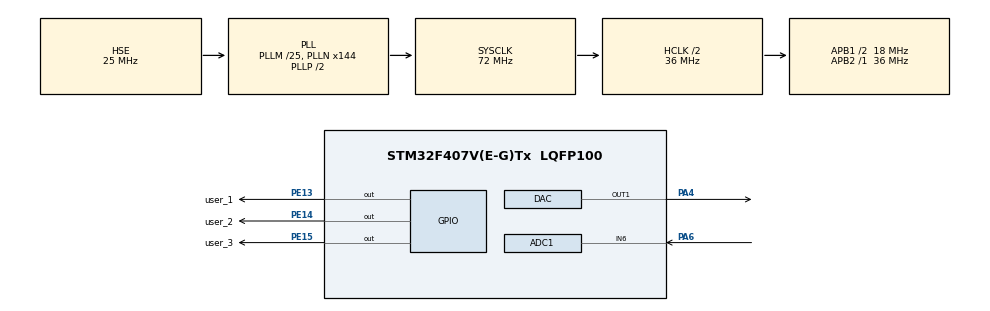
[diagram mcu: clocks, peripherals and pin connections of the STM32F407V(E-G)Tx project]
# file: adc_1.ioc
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ADC1.Channel-3\#ChannelRegularConversion=ADC_CHANNEL_6
ADC1.ClockPrescaler=ADC_CLOCK_SYNC_PCLK_DIV2
ADC1.ContinuousConvMode=ENABLE
ADC1.DMAContinuousRequests=ENABLE
ADC1.DataAlign=ADC_DATAALIGN_RIGHT
ADC1.DiscontinuousConvMode=DISABLE
ADC1.EOCSelection=ADC_EOC_SINGLE_CONV
ADC1.EnableAnalogWatchDog=false
ADC1.ExternalTrigConv=ADC_SOFTWARE_START
ADC1.ExternalTrigConvEdge=ADC_EXTERNALTRIGCONVEDGE_NONE
ADC1.InjNumberOfConversion=0
ADC1.NbrOfConversion=1
ADC1.NbrOfConversionFlag=1
ADC1.Rank-3\#ChannelRegularConversion=1
ADC1.Resolution=ADC_RESOLUTION_12B
ADC1.SamplingTime-3\#ChannelRegularConversion=ADC_SAMPLETIME_3CYCLES
ADC1.ScanConvMode=DISABLE
ADC1.master=1
DAC.DAC_OutputBuffer=DAC_OUTPUTBUFFER_DISABLE
DAC.DAC_Trigger=DAC_TRIGGER_T7_TRGO
DAC.WaveGeneration=DISABLE
Dma.ADC1.1.Direction=DMA_PERIPH_TO_MEMORY
Dma.ADC1.1.FIFOMode=DMA_FIFOMODE_DISABLE
Dma.ADC1.1.Instance=DMA2_Stream0
Dma.ADC1.1.MemDataAlignment=DMA_MDATAALIGN_HALFWORD
Dma.ADC1.1.MemInc=DMA_MINC_ENABLE
Dma.ADC1.1.Mode=DMA_NORMAL
Dma.ADC1.1.PeriphDataAlignment=DMA_PDATAALIGN_HALFWORD
Dma.ADC1.1.PeriphInc=DMA_PINC_DISABLE
Dma.ADC1.1.Priority=DMA_PRIORITY_LOW
Dma.DAC1.0.Direction=DMA_MEMORY_TO_PERIPH
Dma.DAC1.0.FIFOMode=DMA_FIFOMODE_DISABLE
Dma.DAC1.0.Instance=DMA1_Stream5
Dma.DAC1.0.MemDataAlignment=DMA_MDATAALIGN_HALFWORD
Dma.DAC1.0.MemInc=DMA_MINC_ENABLE
Dma.DAC1.0.Mode=DMA_CIRCULAR
Dma.DAC1.0.PeriphDataAlignment=DMA_PDATAALIGN_HALFWORD
Dma.DAC1.0.PeriphInc=DMA_PINC_DISABLE
Dma.DAC1.0.Priority=DMA_PRIORITY_LOW
Dma.Request0=DAC1
Dma.Request1=ADC1
Mcu.Family=STM32F4
Mcu.Name=STM32F407V(E-G)Tx
Mcu.Package=LQFP100
NVIC.DMA1_Stream5_IRQn=true\:0\:0\:false\:false\:true\:false
NVIC.DMA2_Stream0_IRQn=true\:0\:0\:false\:false\:true\:false
NVIC.PriorityGroup=NVIC_PRIORITYGROUP_4
NVIC.TIM7_IRQn=true\:0\:0\:false\:false\:true\:true
PA13.Mode=Serial_Wire
PA13.Signal=SYS_JTMS-SWDIO
PA14.Mode=Serial_Wire
PA14.Signal=SYS_JTCK-SWCLK
PA4.Signal=SharedAnalog_PA4
PA6.Signal=SharedAnalog_PA6
PE13.GPIO_Label=user_1
PE13.GPIO_PuPd=GPIO_NOPULL
PE13.Signal=GPIO_Output
PE14.GPIO_Label=user_2
PE14.GPIO_PuPd=GPIO_NOPULL
PE14.Signal=GPIO_Output
PE15.GPIO_Label=user_3
PE15.GPIO_PuPd=GPIO_NOPULL
PE15.Signal=GPIO_Output
PH0-OSC_IN.Mode=HSE-External-Oscillator
PH0-OSC_IN.Signal=RCC_OSC_IN
PH1-OSC_OUT.Mode=HSE-External-Oscillator
PH1-OSC_OUT.Signal=RCC_OSC_OUT
ProjectManager.HeapSize=0x200
ProjectManager.StackSize=0x400
ProjectManager.TargetToolchain=MDK-ARM V5
RCC.48MHZClocksFreq_Value=36000000
RCC.AHBCLKDivider=RCC_SYSCLK_DIV2
RCC.AHBFreq_Value=36000000
RCC.APB1CLKDivider=RCC_HCLK_DIV2
RCC.APB1Freq_Value=18000000
RCC.APB1TimFreq_Value=36000000
RCC.APB2Freq_Value=36000000
RCC.APB2TimFreq_Value=36000000
RCC.CortexFreq_Value=36000000
RCC.HCLKFreq_Value=36000000
RCC.HSE_VALUE=25000000
RCC.HSI_VALUE=16000000
RCC.LSE_VALUE=32768
RCC.PLLM=25
RCC.PLLN=144
RCC.PLLSourceVirtual=RCC_PLLSOURCE_HSE
RCC.SYSCLKFreq_VALUE=72000000
RCC.SYSCLKSource=RCC_SYSCLKSOURCE_PLLCLK
RCC.VCOOutputFreq_Value=144000000
SH.SharedAnalog_PA4.0=GPIO_Analog
SH.SharedAnalog_PA4.1=DAC_OUT1,DAC_OUT1
SH.SharedAnalog_PA6.0=GPIO_Analog
SH.SharedAnalog_PA6.1=ADC1_IN6,IN6
TIM7.Period=12-1
TIM7.Prescaler=1000-1
TIM7.TIM_MasterOutputTrigger=TIM_TRGO_UPDATE
VP_TIM7_VS_ClockSourceINT.Mode=Enable_Timer
board=custom

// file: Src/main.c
/**
  ******************************************************************************
  * @file           : main.c
  * @brief          : Main program body
  ******************************************************************************
  ** This notice applies to any and all portions of this file
  * that are not between comment pairs USER CODE BEGIN and
  * USER CODE END. Other portions of this file, whether
  * inserted by the user or by software development tools
  * are owned by their respective copyright owners.
  *
  * COPYRIGHT(c) 2021 STMicroelectronics
  *
  * Redistribution and use in source and binary forms, with or without modification,
  * are permitted provided that the following conditions are met:
  *   1. Redistributions of source code must retain the above copyright notice,
  *      this list of conditions and the following disclaimer.
  *   2. Redistributions in binary form must reproduce the above copyright notice,
  *      this list of conditions and the following disclaimer in the documentation
  *      and/or other materials provided with the distribution.
  *   3. Neither the name of STMicroelectronics nor the names of its contributors
  *      may be used to endorse or promote products derived from this software
  *      without specific prior written permission.
  *
  * THIS SOFTWARE IS PROVIDED BY THE COPYRIGHT HOLDERS AND CONTRIBUTORS "AS IS"
  * AND ANY EXPRESS OR IMPLIED WARRANTIES, INCLUDING, BUT NOT LIMITED TO, THE
  * IMPLIED WARRANTIES OF MERCHANTABILITY AND FITNESS FOR A PARTICULAR PURPOSE ARE
  * DISCLAIMED. IN NO EVENT SHALL THE COPYRIGHT HOLDER OR CONTRIBUTORS BE LIABLE
  * FOR ANY DIRECT, INDIRECT, INCIDENTAL, SPECIAL, EXEMPLARY, OR CONSEQUENTIAL
  * DAMAGES (INCLUDING, BUT NOT LIMITED TO, PROCUREMENT OF SUBSTITUTE GOODS OR
  * SERVICES; LOSS OF USE, DATA, OR PROFITS; OR BUSINESS INTERRUPTION) HOWEVER
  * CAUSED AND ON ANY THEORY OF LIABILITY, WHETHER IN CONTRACT, STRICT LIABILITY,
  * OR TORT (INCLUDING NEGLIGENCE OR OTHERWISE) ARISING IN ANY WAY OUT OF THE USE
  * OF THIS SOFTWARE, EVEN IF ADVISED OF THE POSSIBILITY OF SUCH DAMAGE.
  *
  ******************************************************************************
  */
#include "main.h"
#include "stm32f4xx_hal.h"

ADC_HandleTypeDef hadc1;
DMA_HandleTypeDef hdma_adc1;

DAC_HandleTypeDef hdac;
DMA_HandleTypeDef hdma_dac1;

TIM_HandleTypeDef htim7;

/* USER CODE BEGIN PV */
/* Private variables ---------------------------------------------------------*/
 #define adc_buf 4096
	uint32_t adc_Result[adc_buf];
/* USER CODE END PV */

void SystemClock_Config(void);
static void MX_GPIO_Init(void);
static void MX_DMA_Init(void);
static void MX_ADC1_Init(void);
static void MX_DAC_Init(void);
static void MX_TIM7_Init(void);

/* USER CODE BEGIN PFP */
/* Private function prototypes -----------------------------------------------*/

/* USER CODE END PFP */

/* USER CODE BEGIN 0 */
void HAL_TIM_PeriodElapsedCallback(TIM_HandleTypeDef *htim){
	int i = 0;
			HAL_ADC_Start_DMA(&hadc1, (uint32_t *)adc_Result,adc_buf);
 		adc_Result[i] = HAL_ADC_GetValue(&hadc1);

		HAL_ADC_Stop_DMA(&hadc1);

	//	HAL_Delay(1);
		HAL_DAC_Start_DMA(&hdac, DAC1_CHANNEL_1,(uint32_t *)adc_Result, adc_buf, DAC_ALIGN_12B_R);
		HAL_DAC_SetValue(&hdac, DAC1_CHANNEL_1, DAC_ALIGN_12B_R, adc_Result[i]);
		i++;
		if (i==adc_buf)
			i = 0;

}

/* USER CODE END 0 */

int main(void)
{

  /* MCU Configuration----------------------------------------------------------*/

  /* Reset of all peripherals, Initializes the Flash interface and the Systick. */
  HAL_Init();

  /* Configure the system clock */
  SystemClock_Config();

  /* Initialize all configured peripherals */
  MX_GPIO_Init();
  MX_DMA_Init();
  MX_ADC1_Init();
  MX_DAC_Init();
  MX_TIM7_Init();
  /* USER CODE BEGIN 2 */
//	int i = 0;
	HAL_TIM_Base_Start_IT(&htim7);
  /* USER CODE END 2 */

  /* Infinite loop */
  while (1)
  {

	}

}

void SystemClock_Config(void)
{

  RCC_OscInitTypeDef RCC_OscInitStruct;
  RCC_ClkInitTypeDef RCC_ClkInitStruct;

    /**Configure the main internal regulator output voltage
    */
  __HAL_RCC_PWR_CLK_ENABLE();

  __HAL_PWR_VOLTAGESCALING_CONFIG(PWR_REGULATOR_VOLTAGE_SCALE1);

    /**Initializes the CPU, AHB and APB busses clocks
    */
  RCC_OscInitStruct.OscillatorType = RCC_OSCILLATORTYPE_HSE;
  RCC_OscInitStruct.HSEState = RCC_HSE_ON;
  RCC_OscInitStruct.PLL.PLLState = RCC_PLL_ON;
  RCC_OscInitStruct.PLL.PLLSource = RCC_PLLSOURCE_HSE;
  RCC_OscInitStruct.PLL.PLLM = 25;
  RCC_OscInitStruct.PLL.PLLN = 144;
  RCC_OscInitStruct.PLL.PLLP = RCC_PLLP_DIV2;
  RCC_OscInitStruct.PLL.PLLQ = 4;
  if (HAL_RCC_OscConfig(&RCC_OscInitStruct) != HAL_OK)
  {
    _Error_Handler(__FILE__, __LINE__);
  }

    /**Initializes the CPU, AHB and APB busses clocks
    */
  RCC_ClkInitStruct.ClockType = RCC_CLOCKTYPE_HCLK|RCC_CLOCKTYPE_SYSCLK
                              |RCC_CLOCKTYPE_PCLK1|RCC_CLOCKTYPE_PCLK2;
  RCC_ClkInitStruct.SYSCLKSource = RCC_SYSCLKSOURCE_PLLCLK;
  RCC_ClkInitStruct.AHBCLKDivider = RCC_SYSCLK_DIV2;
  RCC_ClkInitStruct.APB1CLKDivider = RCC_HCLK_DIV2;
  RCC_ClkInitStruct.APB2CLKDivider = RCC_HCLK_DIV1;

  if (HAL_RCC_ClockConfig(&RCC_ClkInitStruct, FLASH_LATENCY_1) != HAL_OK)
  {
    _Error_Handler(__FILE__, __LINE__);
  }

    /**Configure the Systick interrupt time
    */
  HAL_SYSTICK_Config(HAL_RCC_GetHCLKFreq()/1000);

    /**Configure the Systick
    */
  HAL_SYSTICK_CLKSourceConfig(SYSTICK_CLKSOURCE_HCLK);

  /* SysTick_IRQn interrupt configuration */
  HAL_NVIC_SetPriority(SysTick_IRQn, 0, 0);
}

/* ADC1 init function */
static void MX_ADC1_Init(void)
{

  ADC_ChannelConfTypeDef sConfig;

    /**Configure the global features of the ADC (Clock, Resolution, Data Alignment and number of conversion)
    */
  hadc1.Instance = ADC1;
  hadc1.Init.ClockPrescaler = ADC_CLOCK_SYNC_PCLK_DIV2;
  hadc1.Init.Resolution = ADC_RESOLUTION_12B;
  hadc1.Init.ScanConvMode = DISABLE;
  hadc1.Init.ContinuousConvMode = ENABLE;
  hadc1.Init.DiscontinuousConvMode = DISABLE;
  hadc1.Init.ExternalTrigConvEdge = ADC_EXTERNALTRIGCONVEDGE_NONE;
  hadc1.Init.ExternalTrigConv = ADC_SOFTWARE_START;
  hadc1.Init.DataAlign = ADC_DATAALIGN_RIGHT;
  hadc1.Init.NbrOfConversion = 1;
  hadc1.Init.DMAContinuousRequests = ENABLE;
  hadc1.Init.EOCSelection = ADC_EOC_SINGLE_CONV;
  if (HAL_ADC_Init(&hadc1) != HAL_OK)
  {
    _Error_Handler(__FILE__, __LINE__);
  }

    /**Configure for the selected ADC regular channel its corresponding rank in the sequencer and its sample time.
    */
  sConfig.Channel = ADC_CHANNEL_6;
  sConfig.Rank = 1;
  sConfig.SamplingTime = ADC_SAMPLETIME_3CYCLES;
  if (HAL_ADC_ConfigChannel(&hadc1, &sConfig) != HAL_OK)
  {
    _Error_Handler(__FILE__, __LINE__);
  }

}

/* DAC init function */
static void MX_DAC_Init(void)
{

  DAC_ChannelConfTypeDef sConfig;

    /**DAC Initialization
    */
  hdac.Instance = DAC;
  if (HAL_DAC_Init(&hdac) != HAL_OK)
  {
    _Error_Handler(__FILE__, __LINE__);
  }

    /**DAC channel OUT1 config
    */
  sConfig.DAC_Trigger = DAC_TRIGGER_T7_TRGO;
  sConfig.DAC_OutputBuffer = DAC_OUTPUTBUFFER_DISABLE;
  if (HAL_DAC_ConfigChannel(&hdac, &sConfig, DAC_CHANNEL_1) != HAL_OK)
  {
    _Error_Handler(__FILE__, __LINE__);
  }

}

/* TIM7 init function */
static void MX_TIM7_Init(void)
{

  TIM_MasterConfigTypeDef sMasterConfig;

  htim7.Instance = TIM7;
  htim7.Init.Prescaler = 1000-1;
  htim7.Init.CounterMode = TIM_COUNTERMODE_UP;
  htim7.Init.Period = 12-1;
  if (HAL_TIM_Base_Init(&htim7) != HAL_OK)
  {
    _Error_Handler(__FILE__, __LINE__);
  }

  sMasterConfig.MasterOutputTrigger = TIM_TRGO_UPDATE;
  sMasterConfig.MasterSlaveMode = TIM_MASTERSLAVEMODE_DISABLE;
  if (HAL_TIMEx_MasterConfigSynchronization(&htim7, &sMasterConfig) != HAL_OK)
  {
    _Error_Handler(__FILE__, __LINE__);
  }

}

static void MX_DMA_Init(void)
{
  /* DMA controller clock enable */
  __HAL_RCC_DMA1_CLK_ENABLE();
  __HAL_RCC_DMA2_CLK_ENABLE();

  /* DMA interrupt init */
  /* DMA1_Stream5_IRQn interrupt configuration */
  HAL_NVIC_SetPriority(DMA1_Stream5_IRQn, 0, 0);
  HAL_NVIC_EnableIRQ(DMA1_Stream5_IRQn);
  /* DMA2_Stream0_IRQn interrupt configuration */
  HAL_NVIC_SetPriority(DMA2_Stream0_IRQn, 0, 0);
  HAL_NVIC_EnableIRQ(DMA2_Stream0_IRQn);

}

/** Configure pins as
        * Analog
        * Input
        * Output
        * EVENT_OUT
        * EXTI
     PA4   ------> SharedAnalog_PA4
     PA6   ------> SharedAnalog_PA6
*/
static void MX_GPIO_Init(void)
{

  GPIO_InitTypeDef GPIO_InitStruct;

  /* GPIO Ports Clock Enable */
  __HAL_RCC_GPIOH_CLK_ENABLE();
  __HAL_RCC_GPIOA_CLK_ENABLE();
  __HAL_RCC_GPIOE_CLK_ENABLE();

  /*Configure GPIO pin Output Level */
  HAL_GPIO_WritePin(GPIOE, user_1_Pin|user_2_Pin|user_3_Pin, GPIO_PIN_RESET);

  /*Configure GPIO pins : PA4 PA6 */
  GPIO_InitStruct.Pin = GPIO_PIN_4|GPIO_PIN_6;
  GPIO_InitStruct.Mode = GPIO_MODE_ANALOG;
  GPIO_InitStruct.Pull = GPIO_NOPULL;
  HAL_GPIO_Init(GPIOA, &GPIO_InitStruct);

  /*Configure GPIO pins : user_1_Pin user_2_Pin user_3_Pin */
  GPIO_InitStruct.Pin = user_1_Pin|user_2_Pin|user_3_Pin;
  GPIO_InitStruct.Mode = GPIO_MODE_OUTPUT_PP;
  GPIO_InitStruct.Pull = GPIO_NOPULL;
  GPIO_InitStruct.Speed = GPIO_SPEED_FREQ_LOW;
  HAL_GPIO_Init(GPIOE, &GPIO_InitStruct);

}

void _Error_Handler(char *file, int line)
{
  while(1)
  {
  }
}

/************************ (C) COPYRIGHT STMicroelectronics *****END OF FILE****/
